# STM32H723VEH6 register map
File version: 1.0
Registers are 32-bit, access not given, reset 0x0 unless marked. A register's access mark holds for its fields unless they carry their own. Offsets are from the block's base; [hi:lo] are bit positions; {n}, {i} and the like mark numbered series; 'fields as' and 'values as' point back to an identical list.

## OCTOSPI1
Base 0x52005000
Same registers: OCTOSPI2 0x5200A000, OCTOSPI 0x5200B400
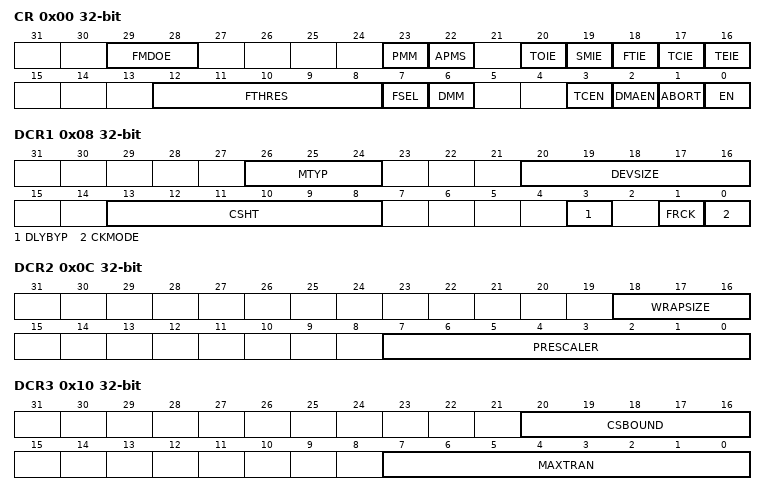
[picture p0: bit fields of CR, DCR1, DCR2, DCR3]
0x00 CR
  [29:28] FMDOE, [23] PMM, [22] APMS, [20] TOIE, [19] SMIE, [18] FTIE, [17] TCIE, [16] TEIE, [12:8] FTHRES, [7] FSEL, [6] DMM, [3] TCEN, [2] DMAEN, [1] ABORT, [0] EN
0x08 DCR1
  [26:24] MTYP, [20:16] DEVSIZE, [13:8] CSHT, [3] DLYBYP, [1] FRCK, [0] CKMODE
0x0C DCR2
  [18:16] WRAPSIZE, [7:0] PRESCALER
0x10 DCR3
  [20:16] CSBOUND, [7:0] MAXTRAN
0x14 DCR4
  [31:0] REFRESH
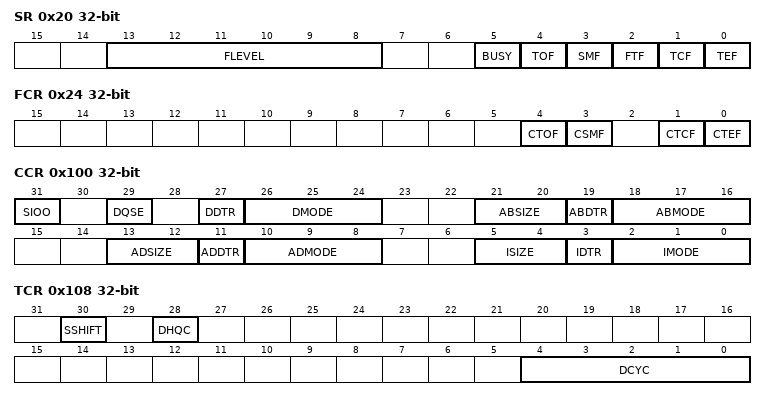
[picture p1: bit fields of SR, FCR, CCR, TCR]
0x20 SR
  [13:8] FLEVEL, [5] BUSY, [4] TOF, [3] SMF, [2] FTF, [1] TCF, [0] TEF
0x24 FCR
  [4] CTOF, [3] CSMF, [1] CTCF, [0] CTEF
0x40 DLR
  [31:0] DL
0x48 AR
  [31:0] ADDRESS
0x50 DR
  [31:0] DATA
0x80 PSMKR
  [31:0] MASK
0x88 PSMAR
  [31:0] MATCH
0x90 PIR
  [15:0] INTERVAL
0x100 CCR
  [31] SIOO, [29] DQSE, [27] DDTR, [26:24] DMODE, [21:20] ABSIZE, [19] ABDTR, [18:16] ABMODE, [13:12] ADSIZE, [11] ADDTR, [10:8] ADMODE, [5:4] ISIZE, [3] IDTR, [2:0] IMODE
0x108 TCR
  [30] SSHIFT, [28] DHQC, [4:0] DCYC
0x110 IR
  [31:0] INSTRUCTION
0x120 ABR
  [31:0] ALTERNATE
0x130 LPTR
  [15:0] TIMEOUT
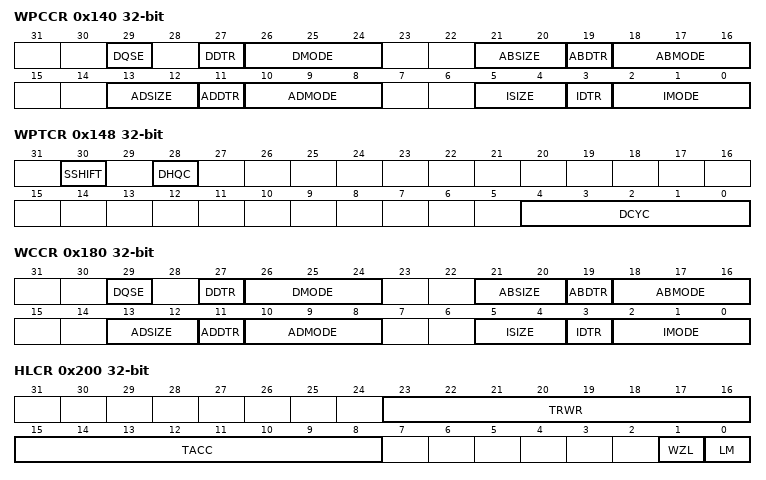
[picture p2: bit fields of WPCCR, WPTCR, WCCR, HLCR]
0x140 WPCCR
  [29] DQSE, [27] DDTR, [26:24] DMODE, [21:20] ABSIZE, [19] ABDTR, [18:16] ABMODE, [13:12] ADSIZE, [11] ADDTR, [10:8] ADMODE, [5:4] ISIZE, [3] IDTR, [2:0] IMODE
0x148 WPTCR
  [30] SSHIFT, [28] DHQC, [4:0] DCYC
0x150 WPIR
  [31:0] INSTRUCTION
0x160 WPABR
  [31:0] ALTERNATE
0x180 WCCR
  fields as WPCCR
0x188 WTCR
  [4:0] DCYC
0x190 WIR
  [31:0] INSTRUCTION
0x1A0 WABR
  [31:0] ALTERNATE
0x200 HLCR
  [23:16] TRWR, [15:8] TACC, [1] WZL, [0] LM

## OTFDEC1
Base 0x5200B800
Same registers: OTFDEC2 0x5200BC00
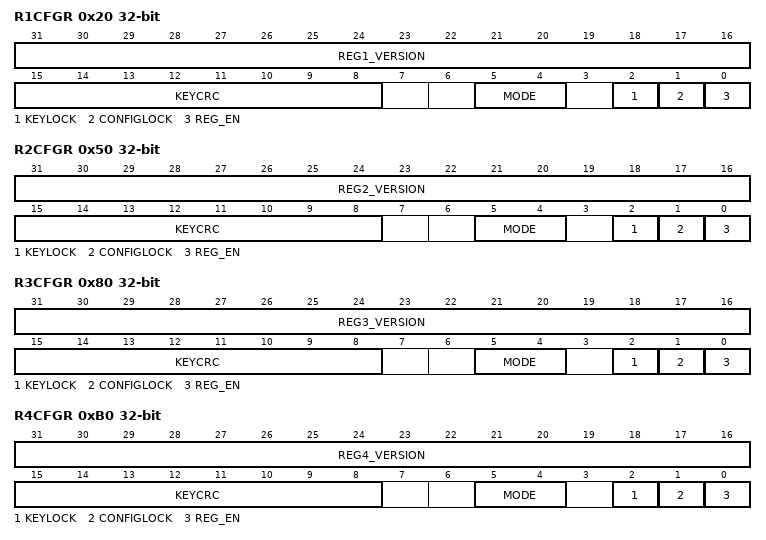
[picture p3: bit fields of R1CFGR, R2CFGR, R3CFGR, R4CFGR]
0x20 R1CFGR
  [31:16] REG1_VERSION, [15:8] KEYCRC, [5:4] MODE, [2] KEYLOCK, [1] CONFIGLOCK, [0] REG_EN
0x24 R1STARTADDR
  [31:0] REG1_START_ADD
0x28 R1ENDADDR
  [31:0] REG1_END_ADD
0x2C R1NONCER0
  [31:0] REG1_NONCE
{0x0+0x30*i} R{i}NONCER1 (i=1..4)
  [31:0] REG{i}_NONCE
{0x34+4i} R1KEYR{i} (i=0..2)
  [31:0] REG1_KEY
0x40 REG1_KEYR3
  [31:0] REG1_KEY
0x50 R2CFGR
  [31:16] REG2_VERSION, [15:8] KEYCRC, [5:4] MODE, [2] KEYLOCK, [1] CONFIGLOCK, [0] REG_EN
0x54 R2STARTADDR
  [31:0] REG2_START_ADD
0x58 R2ENDADDR
  [31:0] REG2_END_ADD
0x5C R2NONCER0
  [31:0] REG2_NONCE
{0x64+4i} R2KEYR{i} (i=0..3)
  [31:0] REG2_KEY
0x80 R3CFGR
  [31:16] REG3_VERSION, [15:8] KEYCRC, [5:4] MODE, [2] KEYLOCK, [1] CONFIGLOCK, [0] REG_EN
0x84 R3STARTADDR
  [31:0] REG3_START_ADD
0x88 R3ENDADDR
  [31:0] REG3_END_ADD
0x8C R3NONCER0
  [31:0] REG3_NONCE
{0x94+4i} R3KEYR{i} (i=0..2)
  [31:0] REG3_KEY
0xA0 REG3_KEYR3
  [31:0] REG3_KEY
0xB0 R4CFGR
  [31:16] REG4_VERSION, [15:8] KEYCRC, [5:4] MODE, [2] KEYLOCK, [1] CONFIGLOCK, [0] REG_EN
0xB4 R4STARTADDR
  [31:0] REG4_START_ADD
0xB8 R4ENDADDR
  [31:0] REG4_END_ADD
0xBC R4NONCER0
  [31:0] REG4_NONCE
{0xC4+4i} R4KEYR{i} (i=0..3)
  [31:0] REG4_KEY
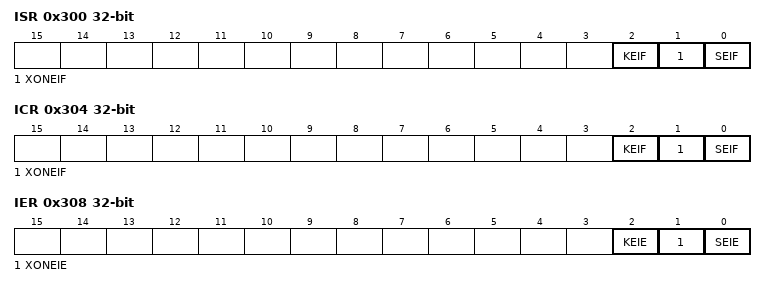
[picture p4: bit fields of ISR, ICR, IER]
0x300 ISR
  [2] KEIF, [1] XONEIF, [0] SEIF
0x304 ICR
  [2] KEIF, [1] XONEIF, [0] SEIF
0x308 IER
  [2] KEIE, [1] XONEIE, [0] SEIE

## EXTI
Base 0x58000000
0x00 RTSR1
  [21:0] TR
0x04 FTSR1
  [21:0] TR
0x08 SWIER1
  [21:0] SWIER
0x0C D3PMR1
  [25:0] MR
0x10 D3PCR1L
  [31:0] PCS
0x14 D3PCR1H
  [19:6] PCS
0x20 RTSR2
  [19:17] TR
0x24 FTSR2
  [19:17] TR
0x28 SWIER2
  [19:17] SWIER
0x2C D3PMR2
  [21:2] MR
0x30 D3PCR2L
  [19:4] PCS
0x34 D3PCR2H
  [11:0] PCS
0x40 RTSR3
  [22:21] TR
0x44 FTSR3
  [22:21] TR
0x48 SWIER3
  [22:21] SWIER
0x4C D3PMR3
  [24] MR
0x50 D3PCR3L
0x54 D3PCR3H
  [17:16] PCS
0x80 CPUIMR1
  [31:0] MR
0x84 CPUCPUEMR1
  [31:0] MR
0x88 CPUPR1
  [21:0] PR
0x90 CPUIMR2
  [31:0] MR
0x94 CPUEMR2
  [31:0] MR
0x98 CPUPR2
  [19:17] PR
0xA0 CPUIMR3
  [27:0] MR
0xA4 CPUEMR3
  [27:0] MR
0xA8 CPUPR3
  [22:20] PR

## SYSCFG
Base 0x58000400
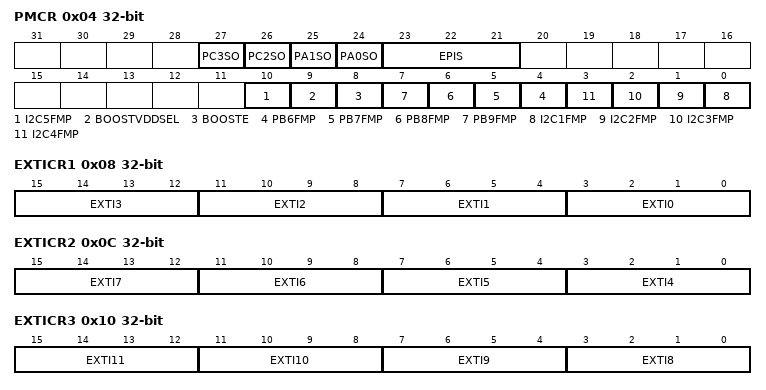
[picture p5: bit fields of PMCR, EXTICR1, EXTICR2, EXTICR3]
0x04 PMCR
  [27] PC3SO, [26] PC2SO, [25] PA1SO, [24] PA0SO, [23:21] EPIS, [10] I2C5FMP, [9] BOOSTVDDSEL, [8] BOOSTE, [n-2] PB{n}FMP (n=6..9), [n-1] I2C{n}FMP (n=1..4)
0x08 EXTICR1
  [4n+3:4n] EXTI{n} (n=0..3)
0x0C EXTICR2
  [4n-13:4n-16] EXTI{n} (n=4..7)
0x10 EXTICR3
  [4n-29:4n-32] EXTI{n} (n=8..11)
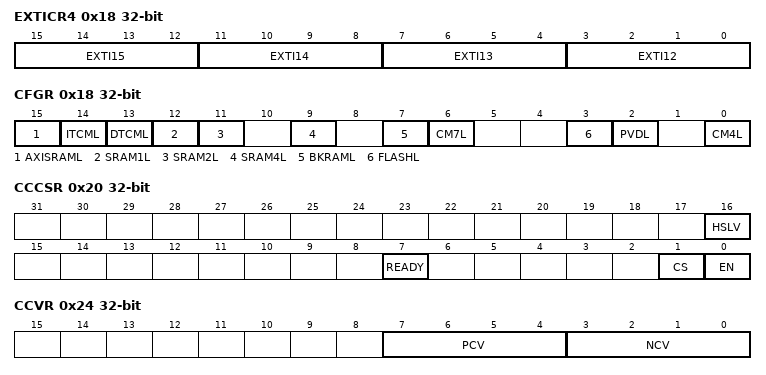
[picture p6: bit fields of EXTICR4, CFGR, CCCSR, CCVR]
0x18 EXTICR4
  [4n-45:4n-48] EXTI{n} (n=12..15)
0x18 CFGR
  [15] AXISRAML, [14] ITCML, [13] DTCML, [12] SRAM1L, [11] SRAM2L, [9] SRAM4L, [7] BKRAML, [6] CM7L, [3] FLASHL, [2] PVDL, [0] CM4L
0x20 CCCSR
  [16] HSLV, [7] READY, [1] CS, [0] EN
0x24 CCVR
  [7:4] PCV, [3:0] NCV
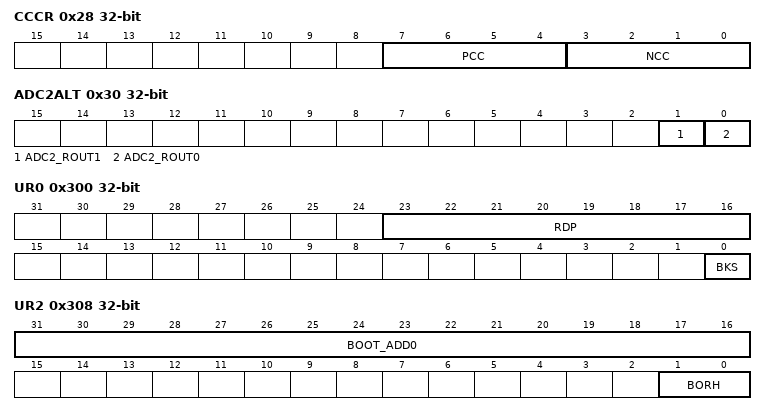
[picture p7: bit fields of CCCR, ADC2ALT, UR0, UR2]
0x28 CCCR
  [7:4] PCC, [3:0] NCC
0x30 ADC2ALT
  [1] ADC2_ROUT1, [0] ADC2_ROUT0
0x124 PKGR
  [3:0] PKG
0x300 UR0
  [23:16] RDP, [0] BKS
0x308 UR2
  [31:16] BOOT_ADD0, [1:0] BORH
0x30C UR3
  [15:0] BOOT_ADD1
0x310 UR4
  [16] MEPAD_1
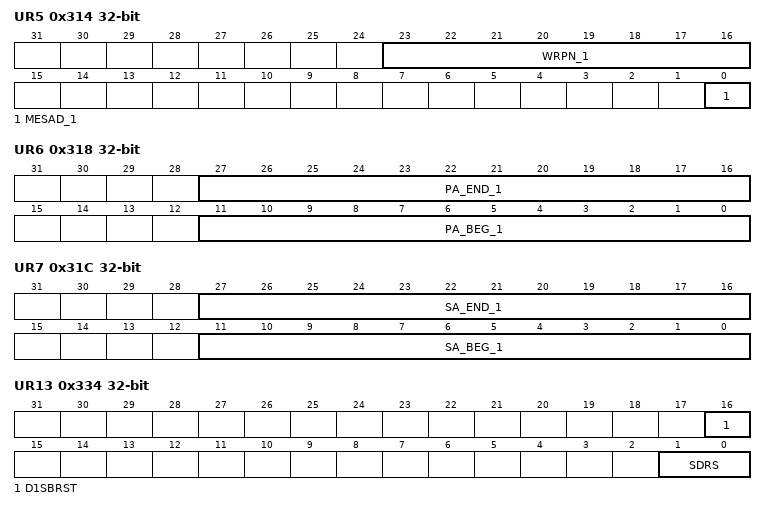
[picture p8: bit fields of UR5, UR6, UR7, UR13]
0x314 UR5
  [23:16] WRPN_1, [0] MESAD_1
0x318 UR6
  [27:16] PA_END_1, [11:0] PA_BEG_1
0x31C UR7
  [27:16] SA_END_1, [11:0] SA_BEG_1
0x32C UR11
  [16] IWDG1M
0x330 UR12
  [16] SECURE
0x334 UR13
  [16] D1SBRST, [1:0] SDRS
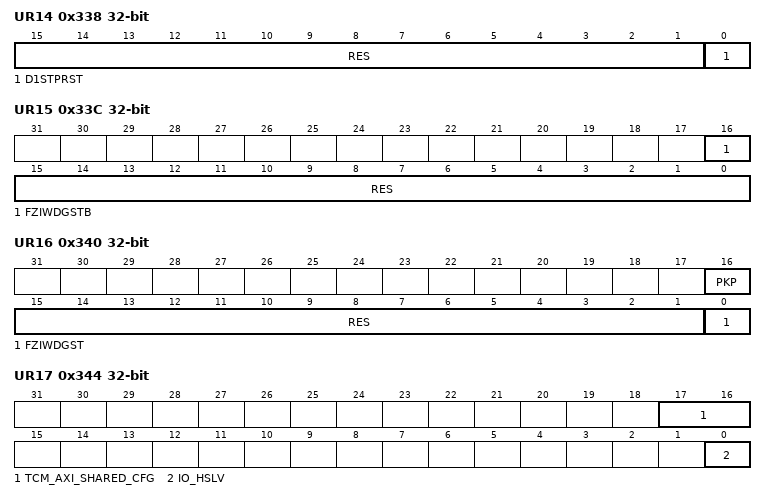
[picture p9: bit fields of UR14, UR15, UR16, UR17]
0x338 UR14
  [15:1] RES, [0] D1STPRST
0x33C UR15
  [16] FZIWDGSTB, [15:0] RES
0x340 UR16
  [16] PKP, [15:1] RES, [0] FZIWDGST
0x344 UR17
  [17:16] TCM_AXI_SHARED_CFG, [0] IO_HSLV
